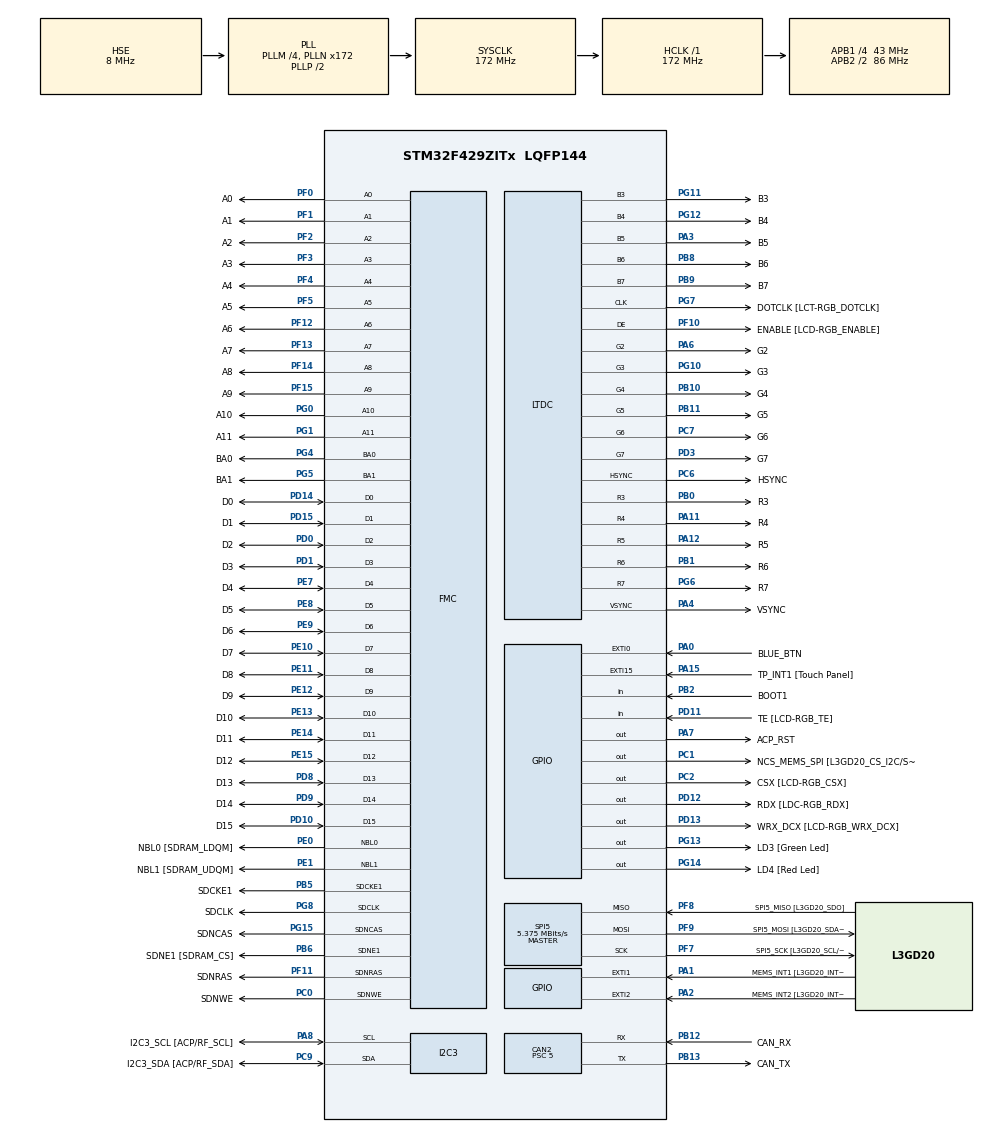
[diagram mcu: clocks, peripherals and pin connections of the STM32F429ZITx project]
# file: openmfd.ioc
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CAN2.BS1=CAN_BS1_15TQ
CAN2.BS2=CAN_BS2_2TQ
CAN2.CalculateBaudRate=477777
CAN2.CalculateTimeBit=2093
CAN2.CalculateTimeQuantum=116.27906976744185
CAN2.Prescaler=5
CAN2.SJW=CAN_SJW_1TQ
FMC.CASLatency1=FMC_SDRAM_CAS_LATENCY_3
FMC.ExitSelfRefreshDelay1=7
FMC.LoadToActiveDelay1=2
FMC.RCDDelay1=2
FMC.RPDelay1=2
FMC.RPDelay2=2
FMC.ReadBurst1=FMC_SDRAM_RBURST_DISABLE
FMC.ReadPipeDelay1=FMC_SDRAM_RPIPE_DELAY_1
FMC.ReadPipeDelay2=FMC_SDRAM_RPIPE_DELAY_1
FMC.RowCycleDelay1=7
FMC.RowCycleDelay2=7
FMC.SDClockPeriod1=FMC_SDRAM_CLOCK_PERIOD_2
FMC.SDClockPeriod2=FMC_SDRAM_CLOCK_PERIOD_2
FMC.SelfRefreshTime1=4
FMC.WriteRecoveryTime1=3
FREERTOS.Queues01=DataQueue,16,uint16_t,0,Dynamic,NULL,NULL
FREERTOS.Tasks01=hardwareTask,24,512,StartHardwareTask,Default,NULL,Dynamic,NULL,NULL;touchGFXTask,24,8192,StartTGFXTask,Default,NULL,Dynamic,NULL,NULL;lcdDebugTask,24,512,StartLcdDebugTask,Default,NULL,Dynamic,NULL,NULL
FREERTOS.configCHECK_FOR_STACK_OVERFLOW=2
FREERTOS.configTOTAL_HEAP_SIZE=64000
FREERTOS.configUSE_APPLICATION_TASK_TAG=1
FREERTOS.configUSE_COUNTING_SEMAPHORES=1
FREERTOS.configUSE_IDLE_HOOK=1
FREERTOS.configUSE_MALLOC_FAILED_HOOK=1
FREERTOS.configUSE_RECURSIVE_MUTEXES=1
LTDC.ActiveH=240
LTDC.ActiveW=320
LTDC.Alpha_L0=255
LTDC.BlendingFactor1_L0=LTDC_BLENDING_FACTOR1_CA
LTDC.BlendingFactor2_L0=LTDC_BLENDING_FACTOR2_CA
LTDC.DEPolarity=LTDC_DEPOLARITY_AL
LTDC.FBStartAdress_L0=0xD0000000
LTDC.HBP=59
LTDC.HFP=16
LTDC.HSPolarity=LTDC_HSPOLARITY_AL
LTDC.HSync=31
LTDC.ImageHeight_L0=234
LTDC.ImageWidth_L0=320
LTDC.Layers=0
LTDC.PCPolarity=LTDC_PCPOLARITY_IPC
LTDC.PixelFormat_L0=LTDC_PIXEL_FORMAT_RGB565
LTDC.VBP=15
LTDC.VFP=4
LTDC.VSPolarity=LTDC_VSPOLARITY_AL
LTDC.VSync=3
LTDC.WindowX0_L0=0
LTDC.WindowX1_L0=320
LTDC.WindowY0_L0=0
LTDC.WindowY1_L0=234
Mcu.Family=STM32F4
Mcu.Name=STM32F429ZITx
Mcu.Package=LQFP144
NVIC.CAN2_RX0_IRQn=true\:5\:0\:false\:false\:true\:true\:true\:true\:true
NVIC.DMA2D_IRQn=true\:5\:0\:true\:false\:true\:true\:true\:true\:true
NVIC.EXTI0_IRQn=true\:5\:0\:false\:false\:true\:true\:true\:true\:true
NVIC.LTDC_IRQn=true\:5\:0\:true\:false\:true\:true\:true\:true\:true
NVIC.PriorityGroup=NVIC_PRIORITYGROUP_4
NVIC.TIM6_DAC_IRQn=true\:0\:0\:false\:false\:true\:false\:false\:true\:true
NVIC.TimeBase=TIM6_DAC_IRQn
NVIC.TimeBaseIP=TIM6
PA0/WKUP.GPIO_Label=BLUE_BTN
PA0/WKUP.GPIO_ModeDefaultEXTI=GPIO_MODE_IT_FALLING
PA0/WKUP.Signal=GPXTI0
PA1.GPIO_Label=MEMS_INT1 [L3GD20_INT1]
PA1.GPIO_ModeDefaultEXTI=GPIO_MODE_EVT_RISING
PA1.GPIO_PuPd=GPIO_NOPULL
PA1.Signal=GPXTI1
PA11.GPIO_Label=R4
PA11.GPIO_Mode=GPIO_MODE_AF_PP
PA11.GPIO_PuPd=GPIO_NOPULL
PA11.GPIO_Speed=GPIO_SPEED_FREQ_VERY_HIGH
PA11.Mode=RGB565
PA11.Signal=LTDC_R4
PA12.GPIO_Label=R5
PA12.GPIO_Mode=GPIO_MODE_AF_PP
PA12.GPIO_PuPd=GPIO_NOPULL
PA12.GPIO_Speed=GPIO_SPEED_FREQ_VERY_HIGH
PA12.Mode=RGB565
PA12.Signal=LTDC_R5
PA13.GPIO_Label=SWDIO
PA13.Mode=Serial_Wire
PA13.Signal=SYS_JTMS-SWDIO
PA14.GPIO_Label=SWCLK
PA14.Mode=Serial_Wire
PA14.Signal=SYS_JTCK-SWCLK
PA15.GPIO_Label=TP_INT1 [Touch Panel]
PA15.GPIO_ModeDefaultEXTI=GPIO_MODE_EVT_RISING
PA15.GPIO_PuPd=GPIO_NOPULL
PA15.Signal=GPXTI15
PA2.GPIO_Label=MEMS_INT2 [L3GD20_INT2]
PA2.GPIO_ModeDefaultEXTI=GPIO_MODE_EVT_RISING
PA2.GPIO_PuPd=GPIO_NOPULL
PA2.Signal=GPXTI2
PA3.GPIO_Label=B5
PA3.GPIO_Mode=GPIO_MODE_AF_PP
PA3.GPIO_PuPd=GPIO_NOPULL
PA3.GPIO_Speed=GPIO_SPEED_FREQ_LOW
PA3.Mode=RGB565
PA3.Signal=LTDC_B5
PA4.GPIO_Label=VSYNC
PA4.GPIO_Mode=GPIO_MODE_AF_PP
PA4.GPIO_PuPd=GPIO_NOPULL
PA4.GPIO_Speed=GPIO_SPEED_FREQ_LOW
PA4.Mode=RGB565
PA4.Signal=LTDC_VSYNC
PA6.GPIO_Label=G2
PA6.GPIO_Mode=GPIO_MODE_AF_PP
PA6.GPIO_PuPd=GPIO_NOPULL
PA6.GPIO_Speed=GPIO_SPEED_FREQ_VERY_HIGH
PA6.Mode=RGB565
PA6.Signal=LTDC_G2
PA7.GPIO_Label=ACP_RST
PA7.GPIO_Mode=GPIO_MODE_OUTPUT_PP
PA7.GPIO_PuPd=GPIO_NOPULL
PA7.GPIO_Speed=GPIO_SPEED_FREQ_LOW
PA7.Signal=GPIO_Output
PA8.GPIO_Label=I2C3_SCL [ACP/RF_SCL]
PA8.GPIO_Mode=GPIO_MODE_AF_OD
PA8.GPIO_Pu=GPIO_PULLUP
PA8.GPIO_PuPd=GPIO_NOPULL
PA8.GPIO_Speed=GPIO_SPEED_FREQ_LOW
PA8.Mode=I2C
PA8.Signal=I2C3_SCL
PB0.GPIO_Label=R3
PB0.GPIO_Mode=GPIO_MODE_AF_PP
PB0.GPIO_PuPd=GPIO_NOPULL
PB0.GPIO_Speed=GPIO_SPEED_FREQ_VERY_HIGH
PB0.Mode=RGB565
PB0.Signal=LTDC_R3
PB1.GPIO_Label=R6
PB1.GPIO_Mode=GPIO_MODE_AF_PP
PB1.GPIO_PuPd=GPIO_NOPULL
PB1.GPIO_Speed=GPIO_SPEED_FREQ_VERY_HIGH
PB1.Mode=RGB565
PB1.Signal=LTDC_R6
PB10.GPIO_Label=G4
PB10.GPIO_Mode=GPIO_MODE_AF_PP
PB10.GPIO_PuPd=GPIO_NOPULL
PB10.GPIO_Speed=GPIO_SPEED_FREQ_VERY_HIGH
PB10.Mode=RGB565
PB10.Signal=LTDC_G4
PB11.GPIO_Label=G5
PB11.GPIO_Mode=GPIO_MODE_AF_PP
PB11.GPIO_PuPd=GPIO_NOPULL
PB11.GPIO_Speed=GPIO_SPEED_FREQ_VERY_HIGH
PB11.Mode=RGB565
PB11.Signal=LTDC_G5
PB12.GPIO_Label=CAN_RX
PB12.GPIO_Speed=GPIO_SPEED_FREQ_VERY_HIGH
PB12.Mode=CAN_Activate
PB12.Signal=CAN2_RX
PB13.GPIO_Label=CAN_TX
PB13.GPIO_Mode=GPIO_MODE_AF_PP
PB13.Mode=CAN_Activate
PB13.Signal=CAN2_TX
PB2/BOOT1.GPIO_Label=BOOT1
PB2/BOOT1.GPIO_Mode=GPIO_MODE_INPUT
PB2/BOOT1.GPIO_PuPd=GPIO_NOPULL
PB2/BOOT1.Signal=GPIO_Input
PB5.GPIO_Label=SDCKE1
PB5.GPIO_Mode=GPIO_MODE_AF_PP
PB5.GPIO_PuPd=GPIO_NOPULL
PB5.GPIO_Speed=GPIO_SPEED_FREQ_VERY_HIGH
PB5.Mode=SdramChipSelect2_1
PB5.Signal=FMC_SDCKE1
PB6.GPIO_Label=SDNE1 [SDRAM_CS]
PB6.GPIO_Mode=GPIO_MODE_AF_PP
PB6.GPIO_PuPd=GPIO_NOPULL
PB6.GPIO_Speed=GPIO_SPEED_FREQ_VERY_HIGH
PB6.Mode=SdramChipSelect2_1
PB6.Signal=FMC_SDNE1
PB8.GPIO_Label=B6
PB8.GPIO_Mode=GPIO_MODE_AF_PP
PB8.GPIO_PuPd=GPIO_NOPULL
PB8.GPIO_Speed=GPIO_SPEED_FREQ_VERY_HIGH
PB8.Mode=RGB565
PB8.Signal=LTDC_B6
PB9.GPIO_Label=B7
PB9.GPIO_Mode=GPIO_MODE_AF_PP
PB9.GPIO_PuPd=GPIO_NOPULL
PB9.GPIO_Speed=GPIO_SPEED_FREQ_VERY_HIGH
PB9.Mode=RGB565
PB9.Signal=LTDC_B7
PC0.GPIO_Label=SDNWE
PC0.GPIO_Mode=GPIO_MODE_AF_PP
PC0.GPIO_PuPd=GPIO_NOPULL
PC0.GPIO_Speed=GPIO_SPEED_FREQ_VERY_HIGH
PC0.Signal=FMC_SDNWE
PC1.GPIO_Label=NCS_MEMS_SPI [L3GD20_CS_I2C/SPI]
PC1.GPIO_Mode=GPIO_MODE_OUTPUT_PP
PC1.GPIO_PuPd=GPIO_NOPULL
PC1.GPIO_Speed=GPIO_SPEED_FREQ_LOW
PC1.Signal=GPIO_Output
PC10.GPIO_Label=R2
PC10.GPIO_Mode=GPIO_MODE_AF_PP
PC10.GPIO_PuPd=GPIO_NOPULL
PC10.GPIO_Speed=GPIO_SPEED_FREQ_LOW
PC10.Signal=LTDC_R2
PC2.GPIO_Label=CSX [LCD-RGB_CSX]
PC2.GPIO_Mode=GPIO_MODE_OUTPUT_PP
PC2.GPIO_PuPd=GPIO_NOPULL
PC2.GPIO_Speed=GPIO_SPEED_FREQ_LOW
PC2.Signal=GPIO_Output
PC6.GPIO_Label=HSYNC
PC6.GPIO_Mode=GPIO_MODE_AF_PP
PC6.GPIO_PuPd=GPIO_NOPULL
PC6.GPIO_Speed=GPIO_SPEED_FREQ_VERY_HIGH
PC6.Mode=RGB565
PC6.Signal=LTDC_HSYNC
PC7.GPIO_Label=G6
PC7.GPIO_Mode=GPIO_MODE_AF_PP
PC7.GPIO_PuPd=GPIO_NOPULL
PC7.GPIO_Speed=GPIO_SPEED_FREQ_VERY_HIGH
PC7.Mode=RGB565
PC7.Signal=LTDC_G6
PC9.GPIO_Label=I2C3_SDA [ACP/RF_SDA]
PC9.GPIO_Mode=GPIO_MODE_AF_OD
PC9.GPIO_Pu=GPIO_PULLUP
PC9.GPIO_PuPd=GPIO_NOPULL
PC9.GPIO_Speed=GPIO_SPEED_FREQ_LOW
PC9.Mode=I2C
PC9.Signal=I2C3_SDA
PD0.GPIO_Label=D2
PD0.GPIO_Mode=GPIO_MODE_AF_PP
PD0.GPIO_PuPd=GPIO_NOPULL
PD0.GPIO_Speed=GPIO_SPEED_FREQ_VERY_HIGH
PD0.Signal=FMC_D2_DA2
PD1.GPIO_Label=D3
PD1.GPIO_Mode=GPIO_MODE_AF_PP
PD1.GPIO_PuPd=GPIO_NOPULL
PD1.GPIO_Speed=GPIO_SPEED_FREQ_VERY_HIGH
PD1.Signal=FMC_D3_DA3
PD10.GPIO_Label=D15
PD10.GPIO_Mode=GPIO_MODE_AF_PP
PD10.GPIO_PuPd=GPIO_NOPULL
PD10.GPIO_Speed=GPIO_SPEED_FREQ_VERY_HIGH
PD10.Signal=FMC_D15_DA15
PD11.GPIO_Label=TE [LCD-RGB_TE]
PD11.GPIO_Mode=GPIO_MODE_INPUT
PD11.GPIO_PuPd=GPIO_NOPULL
PD11.Signal=GPIO_Input
PD12.GPIO_Label=RDX [LDC-RGB_RDX]
PD12.GPIO_Mode=GPIO_MODE_OUTPUT_PP
PD12.GPIO_PuPd=GPIO_NOPULL
PD12.GPIO_Speed=GPIO_SPEED_FREQ_LOW
PD12.Signal=GPIO_Output
PD13.GPIO_Label=WRX_DCX [LCD-RGB_WRX_DCX]
PD13.GPIO_Mode=GPIO_MODE_OUTPUT_PP
PD13.GPIO_PuPd=GPIO_NOPULL
PD13.GPIO_Speed=GPIO_SPEED_FREQ_LOW
PD13.Signal=GPIO_Output
PD14.GPIO_Label=D0
PD14.GPIO_Mode=GPIO_MODE_AF_PP
PD14.GPIO_PuPd=GPIO_NOPULL
PD14.GPIO_Speed=GPIO_SPEED_FREQ_VERY_HIGH
PD14.Signal=FMC_D0_DA0
PD15.GPIO_Label=D1
PD15.GPIO_Mode=GPIO_MODE_AF_PP
PD15.GPIO_PuPd=GPIO_NOPULL
PD15.GPIO_Speed=GPIO_SPEED_FREQ_VERY_HIGH
PD15.Signal=FMC_D1_DA1
PD3.GPIO_Label=G7
PD3.GPIO_Mode=GPIO_MODE_AF_PP
PD3.GPIO_PuPd=GPIO_NOPULL
PD3.GPIO_Speed=GPIO_SPEED_FREQ_VERY_HIGH
PD3.Mode=RGB565
PD3.Signal=LTDC_G7
PD6.GPIO_Label=B2
PD6.GPIO_Mode=GPIO_MODE_AF_PP
PD6.GPIO_PuPd=GPIO_NOPULL
PD6.GPIO_Speed=GPIO_SPEED_FREQ_LOW
PD6.Signal=LTDC_B2
PD8.GPIO_Label=D13
PD8.GPIO_Mode=GPIO_MODE_AF_PP
PD8.GPIO_PuPd=GPIO_NOPULL
PD8.GPIO_Speed=GPIO_SPEED_FREQ_VERY_HIGH
PD8.Signal=FMC_D13_DA13
PD9.GPIO_Label=D14
PD9.GPIO_Mode=GPIO_MODE_AF_PP
PD9.GPIO_PuPd=GPIO_NOPULL
PD9.GPIO_Speed=GPIO_SPEED_FREQ_VERY_HIGH
PD9.Signal=FMC_D14_DA14
PE0.GPIO_Label=NBL0 [SDRAM_LDQM]
PE0.GPIO_Mode=GPIO_MODE_AF_PP
PE0.GPIO_PuPd=GPIO_NOPULL
PE0.GPIO_Speed=GPIO_SPEED_FREQ_VERY_HIGH
PE0.Signal=FMC_NBL0
PE1.GPIO_Label=NBL1 [SDRAM_UDQM]
PE1.GPIO_Mode=GPIO_MODE_AF_PP
PE1.GPIO_PuPd=GPIO_NOPULL
PE1.GPIO_Speed=GPIO_SPEED_FREQ_VERY_HIGH
PE1.Signal=FMC_NBL1
PE10.GPIO_Label=D7
PE10.GPIO_Mode=GPIO_MODE_AF_PP
PE10.GPIO_PuPd=GPIO_NOPULL
PE10.GPIO_Speed=GPIO_SPEED_FREQ_VERY_HIGH
PE10.Signal=FMC_D7_DA7
PE11.GPIO_Label=D8
PE11.GPIO_Mode=GPIO_MODE_AF_PP
PE11.GPIO_PuPd=GPIO_NOPULL
PE11.GPIO_Speed=GPIO_SPEED_FREQ_VERY_HIGH
PE11.Signal=FMC_D8_DA8
PE12.GPIO_Label=D9
PE12.GPIO_Mode=GPIO_MODE_AF_PP
PE12.GPIO_PuPd=GPIO_NOPULL
PE12.GPIO_Speed=GPIO_SPEED_FREQ_VERY_HIGH
PE12.Signal=FMC_D9_DA9
PE13.GPIO_Label=D10
PE13.GPIO_Mode=GPIO_MODE_AF_PP
PE13.GPIO_PuPd=GPIO_NOPULL
PE13.GPIO_Speed=GPIO_SPEED_FREQ_VERY_HIGH
PE13.Signal=FMC_D10_DA10
PE14.GPIO_Label=D11
PE14.GPIO_Mode=GPIO_MODE_AF_PP
PE14.GPIO_PuPd=GPIO_NOPULL
PE14.GPIO_Speed=GPIO_SPEED_FREQ_VERY_HIGH
PE14.Signal=FMC_D11_DA11
PE15.GPIO_Label=D12
PE15.GPIO_Mode=GPIO_MODE_AF_PP
PE15.GPIO_PuPd=GPIO_NOPULL
PE15.GPIO_Speed=GPIO_SPEED_FREQ_VERY_HIGH
PE15.Signal=FMC_D12_DA12
PE7.GPIO_Label=D4
PE7.GPIO_Mode=GPIO_MODE_AF_PP
PE7.GPIO_PuPd=GPIO_NOPULL
PE7.GPIO_Speed=GPIO_SPEED_FREQ_VERY_HIGH
PE7.Signal=FMC_D4_DA4
PE8.GPIO_Label=D5
PE8.GPIO_Mode=GPIO_MODE_AF_PP
PE8.GPIO_PuPd=GPIO_NOPULL
PE8.GPIO_Speed=GPIO_SPEED_FREQ_VERY_HIGH
PE8.Signal=FMC_D5_DA5
PE9.GPIO_Label=D6
PE9.GPIO_Mode=GPIO_MODE_AF_PP
PE9.GPIO_PuPd=GPIO_NOPULL
PE9.GPIO_Speed=GPIO_SPEED_FREQ_VERY_HIGH
PE9.Signal=FMC_D6_DA6
PF0.GPIO_Label=A0
PF0.GPIO_Mode=GPIO_MODE_AF_PP
PF0.GPIO_PuPd=GPIO_NOPULL
PF0.GPIO_Speed=GPIO_SPEED_FREQ_VERY_HIGH
PF0.Signal=FMC_A0
PF1.GPIO_Label=A1
PF1.GPIO_Mode=GPIO_MODE_AF_PP
PF1.GPIO_PuPd=GPIO_NOPULL
PF1.GPIO_Speed=GPIO_SPEED_FREQ_VERY_HIGH
PF1.Signal=FMC_A1
PF10.GPIO_Label=ENABLE [LCD-RGB_ENABLE]
PF10.GPIO_Mode=GPIO_MODE_AF_PP
PF10.GPIO_PuPd=GPIO_NOPULL
PF10.GPIO_Speed=GPIO_SPEED_FREQ_VERY_HIGH
PF10.Mode=RGB565
PF10.Signal=LTDC_DE
PF11.GPIO_Label=SDNRAS
PF11.GPIO_Mode=GPIO_MODE_AF_PP
PF11.GPIO_PuPd=GPIO_NOPULL
PF11.GPIO_Speed=GPIO_SPEED_FREQ_VERY_HIGH
PF11.Signal=FMC_SDNRAS
PF12.GPIO_Label=A6
PF12.GPIO_Mode=GPIO_MODE_AF_PP
PF12.GPIO_PuPd=GPIO_NOPULL
PF12.GPIO_Speed=GPIO_SPEED_FREQ_VERY_HIGH
PF12.Signal=FMC_A6
PF13.GPIO_Label=A7
PF13.GPIO_Mode=GPIO_MODE_AF_PP
PF13.GPIO_PuPd=GPIO_NOPULL
PF13.GPIO_Speed=GPIO_SPEED_FREQ_VERY_HIGH
PF13.Signal=FMC_A7
PF14.GPIO_Label=A8
PF14.GPIO_Mode=GPIO_MODE_AF_PP
PF14.GPIO_PuPd=GPIO_NOPULL
PF14.GPIO_Speed=GPIO_SPEED_FREQ_VERY_HIGH
PF14.Signal=FMC_A8
PF15.GPIO_Label=A9
PF15.GPIO_Mode=GPIO_MODE_AF_PP
PF15.GPIO_PuPd=GPIO_NOPULL
PF15.GPIO_Speed=GPIO_SPEED_FREQ_VERY_HIGH
PF15.Signal=FMC_A9
PF2.GPIO_Label=A2
PF2.GPIO_Mode=GPIO_MODE_AF_PP
PF2.GPIO_PuPd=GPIO_NOPULL
PF2.GPIO_Speed=GPIO_SPEED_FREQ_VERY_HIGH
PF2.Signal=FMC_A2
PF3.GPIO_Label=A3
PF3.GPIO_Mode=GPIO_MODE_AF_PP
PF3.GPIO_PuPd=GPIO_NOPULL
PF3.GPIO_Speed=GPIO_SPEED_FREQ_VERY_HIGH
PF3.Signal=FMC_A3
PF4.GPIO_Label=A4
PF4.GPIO_Mode=GPIO_MODE_AF_PP
PF4.GPIO_PuPd=GPIO_NOPULL
PF4.GPIO_Speed=GPIO_SPEED_FREQ_VERY_HIGH
PF4.Signal=FMC_A4
PF5.GPIO_Label=A5
PF5.GPIO_Mode=GPIO_MODE_AF_PP
PF5.GPIO_PuPd=GPIO_NOPULL
PF5.GPIO_Speed=GPIO_SPEED_FREQ_VERY_HIGH
PF5.Signal=FMC_A5
PF7.GPIO_Label=SPI5_SCK [L3GD20_SCL/SPC]
PF7.GPIO_Mode=GPIO_MODE_AF_PP
PF7.GPIO_PuPd=GPIO_NOPULL
PF7.GPIO_Speed=GPIO_SPEED_FREQ_LOW
PF7.Mode=Full_Duplex_Master
PF7.Signal=SPI5_SCK
PF8.GPIO_Label=SPI5_MISO [L3GD20_SDO]
PF8.GPIO_Mode=GPIO_MODE_AF_PP
PF8.GPIO_PuPd=GPIO_NOPULL
PF8.GPIO_Speed=GPIO_SPEED_FREQ_LOW
PF8.Mode=Full_Duplex_Master
PF8.Signal=SPI5_MISO
PF9.GPIO_Label=SPI5_MOSI [L3GD20_SDA/SDI/SDO]
PF9.GPIO_Mode=GPIO_MODE_AF_PP
PF9.GPIO_PuPd=GPIO_NOPULL
PF9.GPIO_Speed=GPIO_SPEED_FREQ_LOW
PF9.Mode=Full_Duplex_Master
PF9.Signal=SPI5_MOSI
PG0.GPIO_Label=A10
PG0.GPIO_Mode=GPIO_MODE_AF_PP
PG0.GPIO_PuPd=GPIO_NOPULL
PG0.GPIO_Speed=GPIO_SPEED_FREQ_VERY_HIGH
PG0.Signal=FMC_A10
PG1.GPIO_Label=A11
PG1.GPIO_Mode=GPIO_MODE_AF_PP
PG1.GPIO_PuPd=GPIO_NOPULL
PG1.GPIO_Speed=GPIO_SPEED_FREQ_VERY_HIGH
PG1.Signal=FMC_A11
PG10.GPIO_Label=G3
PG10.GPIO_Mode=GPIO_MODE_AF_PP
PG10.GPIO_PuPd=GPIO_NOPULL
PG10.GPIO_Speed=GPIO_SPEED_FREQ_VERY_HIGH
PG10.Mode=RGB565
PG10.Signal=LTDC_G3
PG11.GPIO_Label=B3
PG11.GPIO_Mode=GPIO_MODE_AF_PP
PG11.GPIO_PuPd=GPIO_NOPULL
PG11.GPIO_Speed=GPIO_SPEED_FREQ_VERY_HIGH
PG11.Mode=RGB565
PG11.Signal=LTDC_B3
PG12.GPIO_Label=B4
PG12.GPIO_Mode=GPIO_MODE_AF_PP
PG12.GPIO_PuPd=GPIO_NOPULL
PG12.GPIO_Speed=GPIO_SPEED_FREQ_VERY_HIGH
PG12.Mode=RGB565
PG12.Signal=LTDC_B4
PG13.GPIO_Label=LD3 [Green Led]
PG13.GPIO_Mode=GPIO_MODE_OUTPUT_PP
PG13.GPIO_PuPd=GPIO_NOPULL
PG13.GPIO_Speed=GPIO_SPEED_FREQ_LOW
PG13.Signal=GPIO_Output
PG14.GPIO_Label=LD4 [Red Led]
PG14.GPIO_Mode=GPIO_MODE_OUTPUT_PP
PG14.GPIO_PuPd=GPIO_NOPULL
PG14.GPIO_Speed=GPIO_SPEED_FREQ_LOW
PG14.Signal=GPIO_Output
PG15.GPIO_Label=SDNCAS
PG15.GPIO_Mode=GPIO_MODE_AF_PP
PG15.GPIO_PuPd=GPIO_NOPULL
PG15.GPIO_Speed=GPIO_SPEED_FREQ_VERY_HIGH
PG15.Signal=FMC_SDNCAS
PG4.GPIO_Label=BA0
PG4.GPIO_Mode=GPIO_MODE_AF_PP
PG4.GPIO_PuPd=GPIO_NOPULL
PG4.GPIO_Speed=GPIO_SPEED_FREQ_VERY_HIGH
PG4.Signal=FMC_A14_BA0
PG5.GPIO_Label=BA1
PG5.GPIO_Mode=GPIO_MODE_AF_PP
PG5.GPIO_PuPd=GPIO_NOPULL
PG5.GPIO_Speed=GPIO_SPEED_FREQ_VERY_HIGH
PG5.Signal=FMC_A15_BA1
PG6.GPIO_Label=R7
PG6.GPIO_Mode=GPIO_MODE_AF_PP
PG6.GPIO_PuPd=GPIO_NOPULL
PG6.GPIO_Speed=GPIO_SPEED_FREQ_VERY_HIGH
PG6.Mode=RGB565
PG6.Signal=LTDC_R7
PG7.GPIO_Label=DOTCLK [LCT-RGB_DOTCLK]
PG7.GPIO_Mode=GPIO_MODE_AF_PP
PG7.GPIO_PuPd=GPIO_NOPULL
PG7.GPIO_Speed=GPIO_SPEED_FREQ_VERY_HIGH
PG7.Mode=RGB565
PG7.Signal=LTDC_CLK
PG8.GPIO_Label=SDCLK
PG8.GPIO_Mode=GPIO_MODE_AF_PP
PG8.GPIO_PuPd=GPIO_NOPULL
PG8.GPIO_Speed=GPIO_SPEED_FREQ_VERY_HIGH
PG8.Signal=FMC_SDCLK
PH0/OSC_IN.GPIO_Label=PH0-OSC_IN
PH0/OSC_IN.Mode=HSE-External-Oscillator
PH0/OSC_IN.Signal=RCC_OSC_IN
PH1/OSC_OUT.GPIO_Label=PH1-OSC_OUT
PH1/OSC_OUT.Mode=HSE-External-Oscillator
PH1/OSC_OUT.Signal=RCC_OSC_OUT
ProjectManager.HeapSize=0x200
ProjectManager.StackSize=0x400
ProjectManager.TargetToolchain=STM32CubeIDE
RCC.48MHZClocksFreq_Value=43000000
RCC.AHBFreq_Value=172000000
RCC.APB1CLKDivider=RCC_HCLK_DIV4
RCC.APB1Freq_Value=43000000
RCC.APB1TimFreq_Value=86000000
RCC.APB2CLKDivider=RCC_HCLK_DIV2
RCC.APB2Freq_Value=86000000
RCC.APB2TimFreq_Value=172000000
RCC.CortexFreq_Value=172000000
RCC.HCLKFreq_Value=172000000
RCC.HSE_VALUE=8000000
RCC.HSI_VALUE=16000000
RCC.LSE_VALUE=32768
RCC.PLLM=4
RCC.PLLN=172
RCC.PLLQ=8
RCC.PLLSAIN=54
RCC.PLLSourceVirtual=RCC_PLLSOURCE_HSE
RCC.SYSCLKFreq_VALUE=172000000
RCC.SYSCLKSource=RCC_SYSCLKSOURCE_PLLCLK
RCC.VCOOutputFreq_Value=344000000
SH.FMC_A0.0=FMC_A0,12b-sda1
SH.FMC_A1.0=FMC_A1,12b-sda1
SH.FMC_A10.0=FMC_A10,12b-sda1
SH.FMC_A11.0=FMC_A11,12b-sda1
SH.FMC_A14_BA0.0=FMC_BA0,FourSdramBanks1
SH.FMC_A15_BA1.0=FMC_BA1,FourSdramBanks1
SH.FMC_A2.0=FMC_A2,12b-sda1
SH.FMC_A3.0=FMC_A3,12b-sda1
SH.FMC_A4.0=FMC_A4,12b-sda1
SH.FMC_A5.0=FMC_A5,12b-sda1
SH.FMC_A6.0=FMC_A6,12b-sda1
SH.FMC_A7.0=FMC_A7,12b-sda1
SH.FMC_A8.0=FMC_A8,12b-sda1
SH.FMC_A9.0=FMC_A9,12b-sda1
SH.FMC_D0_DA0.0=FMC_D0,sd-16b-d1
SH.FMC_D10_DA10.0=FMC_D10,sd-16b-d1
SH.FMC_D11_DA11.0=FMC_D11,sd-16b-d1
SH.FMC_D12_DA12.0=FMC_D12,sd-16b-d1
SH.FMC_D13_DA13.0=FMC_D13,sd-16b-d1
SH.FMC_D14_DA14.0=FMC_D14,sd-16b-d1
SH.FMC_D15_DA15.0=FMC_D15,sd-16b-d1
SH.FMC_D1_DA1.0=FMC_D1,sd-16b-d1
SH.FMC_D2_DA2.0=FMC_D2,sd-16b-d1
SH.FMC_D3_DA3.0=FMC_D3,sd-16b-d1
SH.FMC_D4_DA4.0=FMC_D4,sd-16b-d1
SH.FMC_D5_DA5.0=FMC_D5,sd-16b-d1
SH.FMC_D6_DA6.0=FMC_D6,sd-16b-d1
SH.FMC_D7_DA7.0=FMC_D7,sd-16b-d1
SH.FMC_D8_DA8.0=FMC_D8,sd-16b-d1
SH.FMC_D9_DA9.0=FMC_D9,sd-16b-d1
SH.FMC_NBL0.0=FMC_NBL0,Sd2ByteEnable1
SH.FMC_NBL1.0=FMC_NBL1,Sd2ByteEnable1
SH.FMC_SDCLK.0=FMC_SDCLK,12b-sda1
SH.FMC_SDNCAS.0=FMC_SDNCAS,12b-sda1
SH.FMC_SDNRAS.0=FMC_SDNRAS,12b-sda1
SH.FMC_SDNWE.0=FMC_SDNWE,12b-sda1
SPI5.BaudRatePrescaler=SPI_BAUDRATEPRESCALER_16
SPI5.CalculateBaudRate=5.375 MBits/s
SPI5.Direction=SPI_DIRECTION_2LINES
SPI5.Mode=SPI_MODE_MASTER
SPI5.VirtualType=VM_MASTER
STMicroelectronics.X-CUBE-TOUCHGFX.4.20.0.ApplicationCcGraphicsJjApplication=TouchGFXOoGenerator
STMicroelectronics.X-CUBE-TOUCHGFX.4.20.0.tgfx_address1=0xD0000000
STMicroelectronics.X-CUBE-TOUCHGFX.4.20.0.tgfx_address2=0xD0025800
STMicroelectronics.X-CUBE-TOUCHGFX.4.20.0.tgfx_buffering_strategy=Double
STMicroelectronics.X-CUBE-TOUCHGFX.4.20.0.tgfx_display_interface=disp_ltdc
STMicroelectronics.X-CUBE-TOUCHGFX.4.20.0.tgfx_hardware_accelerator=dma_2d
STMicroelectronics.X-CUBE-TOUCHGFX.4.20.0.tgfx_location=By Address
STMicroelectronics.X-CUBE-TOUCHGFX.4.20.0.tgfx_vsync=vsync_ltdc
STMicroelectronics.X-CUBE-TOUCHGFX.4.20.0_IsPackSelfContextualization=true
VP_CRC_VS_CRC.Mode=CRC_Activate
VP_DMA2D_VS_DMA2D.Mode=DMA2D_Activate
VP_FREERTOS_VS_CMSIS_V2.Mode=CMSIS_V2
VP_RNG_VS_RNG.Mode=RNG_Activate
VP_STMicroelectronics.X-CUBE-TOUCHGFX_VS_GraphicsJjApplication_4.20.0.Mode=GraphicsJjApplication
VP_SYS_VS_tim6.Mode=TIM6
VP_TIM1_VS_ClockSourceINT.Mode=Internal
board=STM32F429I-DISC1

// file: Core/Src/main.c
/* USER CODE BEGIN Header */
/**
  ******************************************************************************
  * @file           : main.c
  * @brief          : Main program body
  ******************************************************************************
  * @attention
  *
  * Copyright (c) 2022 STMicroelectronics.
  * All rights reserved.
  *
  * This software is licensed under terms that can be found in the LICENSE file
  * in the root directory of this software component.
  * If no LICENSE file comes with this software, it is provided AS-IS.
  *
  ******************************************************************************
  */
/* USER CODE END Header */
#include "main.h"
#include "cmsis_os.h"
#include "app_touchgfx.h"

/* USER CODE BEGIN Includes */
#include "stdbool.h"
#include "comm.h"
#include "ili9341/ili9341.h"
#include "data.h"
#include "debug_screen.h"
#include "debug_data.h"
/* USER CODE END Includes */

/* USER CODE BEGIN PD */
#define REFRESH_COUNT           ((uint32_t)1386)   /* SDRAM refresh counter */
#define SDRAM_TIMEOUT           ((uint32_t)0xFFFF)

/**
  * @brief  FMC SDRAM Mode definition register defines
  */
#define SDRAM_MODEREG_BURST_LENGTH_1             ((uint16_t)0x0000)
#define SDRAM_MODEREG_BURST_LENGTH_2             ((uint16_t)0x0001)
#define SDRAM_MODEREG_BURST_LENGTH_4             ((uint16_t)0x0002)
#define SDRAM_MODEREG_BURST_LENGTH_8             ((uint16_t)0x0004)
#define SDRAM_MODEREG_BURST_TYPE_SEQUENTIAL      ((uint16_t)0x0000)
#define SDRAM_MODEREG_BURST_TYPE_INTERLEAVED     ((uint16_t)0x0008)
#define SDRAM_MODEREG_CAS_LATENCY_2              ((uint16_t)0x0020)
#define SDRAM_MODEREG_CAS_LATENCY_3              ((uint16_t)0x0030)
#define SDRAM_MODEREG_OPERATING_MODE_STANDARD    ((uint16_t)0x0000)
#define SDRAM_MODEREG_WRITEBURST_MODE_PROGRAMMED ((uint16_t)0x0000)
#define SDRAM_MODEREG_WRITEBURST_MODE_SINGLE     ((uint16_t)0x0200)

#define I2C3_TIMEOUT_MAX                    0x3000 /*<! The value of the maximal timeout for I2C waiting loops */
#define SPI5_TIMEOUT_MAX                    0x1000
/* USER CODE END PD */

CAN_HandleTypeDef hcan2;

CRC_HandleTypeDef hcrc;

DMA2D_HandleTypeDef hdma2d;

I2C_HandleTypeDef hi2c3;

LTDC_HandleTypeDef hltdc;

RNG_HandleTypeDef hrng;

SPI_HandleTypeDef hspi5;

TIM_HandleTypeDef htim1;

SDRAM_HandleTypeDef hsdram1;

/* Definitions for hardwareTask */
osThreadId_t hardwareTaskHandle;
const osThreadAttr_t hardwareTask_attributes = {
  .name = "hardwareTask",
  .stack_size = 512 * 4,
  .priority = (osPriority_t) osPriorityNormal,
};
/* Definitions for touchGFXTask */
osThreadId_t touchGFXTaskHandle;
const osThreadAttr_t touchGFXTask_attributes = {
  .name = "touchGFXTask",
  .stack_size = 8192 * 4,
  .priority = (osPriority_t) osPriorityNormal,
};
/* Definitions for lcdDebugTask */
osThreadId_t lcdDebugTaskHandle;
const osThreadAttr_t lcdDebugTask_attributes = {
  .name = "lcdDebugTask",
  .stack_size = 512 * 4,
  .priority = (osPriority_t) osPriorityNormal,
};
/* Definitions for DataQueue */
osMessageQueueId_t DataQueueHandle;
const osMessageQueueAttr_t DataQueue_attributes = {
  .name = "DataQueue"
};

void SystemClock_Config(void);
static void MX_GPIO_Init(void);
static void MX_CRC_Init(void);
static void MX_DMA2D_Init(void);
static void MX_FMC_Init(void);
static void MX_I2C3_Init(void);
static void MX_LTDC_Init(void);
static void MX_SPI5_Init(void);
static void MX_TIM1_Init(void);
static void MX_CAN2_Init(void);
static void MX_RNG_Init(void);
void StartHardwareTask(void *argument);
void StartTGFXTask(void *argument);
void StartLcdDebugTask(void *argument);

/* USER CODE BEGIN PFP */
static void BSP_SDRAM_Initialization_Sequence(SDRAM_HandleTypeDef *hsdram, FMC_SDRAM_CommandTypeDef *Command);

static uint8_t I2C3_ReadData(uint8_t Addr, uint8_t Reg);
static void I2C3_WriteData(uint8_t Addr, uint8_t Reg, uint8_t Value);
static uint8_t I2C3_ReadBuffer(uint8_t Addr, uint8_t Reg, uint8_t *pBuffer, uint16_t Length);

/* IOExpander IO functions */
void IOE_Init(void);
void IOE_ITConfig(void);
void IOE_Delay(uint32_t Delay);
void IOE_Write(uint8_t Addr, uint8_t Reg, uint8_t Value);
uint8_t IOE_Read(uint8_t Addr, uint8_t Reg);
uint16_t IOE_ReadMultiple(uint8_t Addr, uint8_t Reg, uint8_t *pBuffer, uint16_t Length);
/* USER CODE END PFP */

/* USER CODE BEGIN 0 */
uint32_t I2c3Timeout = I2C3_TIMEOUT_MAX; /*<! Value of Timeout when I2C communication fails */

/* USER CODE END 0 */

int main(void)
{

  /* MCU Configuration--------------------------------------------------------*/

  /* Reset of all peripherals, Initializes the Flash interface and the Systick. */
  HAL_Init();

  /* Configure the system clock */
  SystemClock_Config();

  /* Initialize all configured peripherals */
  MX_GPIO_Init();
  MX_CRC_Init();
  MX_DMA2D_Init();
  MX_FMC_Init();
  MX_I2C3_Init();
  MX_LTDC_Init();
  MX_SPI5_Init();
  MX_TIM1_Init();
  MX_CAN2_Init();
  MX_RNG_Init();
  MX_TouchGFX_Init();
  /* Call PreOsInit function */
  MX_TouchGFX_PreOSInit();
  /* USER CODE BEGIN 2 */
  MFD_DataInit();

  // DEBUG Controllers Init
  DBGS_init();
  DBGD_init();

  COMM_init();

  // SW RST
  I2C3_WriteData(0x54, 0x17, 0b00000010);

  // SD Mode Register 1
  I2C3_WriteData(0x54, 0x80, 0x10); // 0b00010000
  // SD standard - NTSC
  // SD luma filter - Luma SSAF
  // SD chroma filter - 1.3 MHz

  // SD Mode Register 2 (0x0B 0b00001011)
  I2C3_WriteData(0x54, 0x82, 0b01001011);
  // SD PrPb SSAF filter - Enabled
  // SD DAC Output 1 - 1
  // SD pedestal - Enabled
  // SD square pixel mode - Disabled
  // SD VCR FF/RW sync - Disabled
  // SD pixel data valid - Disabled
  // SD active video edge control - Disabled

  // SD Mode Register 3
  I2C3_WriteData(0x54, 0x83, 0x04); // 0b00000100
  // SD pedestal YPrPb output - No pedestal on YPrPb
  // SD Output Levels Y - Y = 700 mV/300 mV
  // SD Output Levels PrPb - 700 mV p-p
  // SD vertical blanking interval (VBI) open - Disabled
  // SD closed captioning field control - Closed captioning disabled

  // SD Mode Register 4
  I2C3_WriteData(0x54, 0x84, 0x00); // 0b00000000
  // SD SFL/SCR/TR mode select - Disabled
  // SD active video length - 720 pixels
  // SD chroma - Chroma enabled
  // SD burst - Enabled
  // SD color bars - Disabled
  // SD luma/chroma swap - DAC 2 = luma, DAC 3 = chroma

  // SD Mode Register 5 (0x02 0b00000010)
  I2C3_WriteData(0x54, 0x86, 0b00000010);
  // NTSC color subcarrier adjust - 5.59 μs (must be set for Macrovision compliance)
  // SD EIA/CEA-861B synchronization compliance - Disabled
  // SD horizontal/vertical counter mode (1) - Update field/line counter
  // SD RGB color swap - Normal

  /* (1) When set to 0, the horizontal/vertical counters automatically wrap around at the end of the line/field/frame of the selected standard. When set to 1, the
horizontal/vertical counters are free running and wrap around when external sync signals indicate to do so. */

  // SD Mode Register 6
  I2C3_WriteData(0x54, 0x87, 0x80); // 0b10100000 0xA0 (autodetect) // 0b10000000 0x80 (def)
  // SD Mode Register 7
  I2C3_WriteData(0x54, 0x88, 0x12); // 0b00010010 0x12 (non-interlaced) // 0b00010000 0x10 (interlaced)
  // SD Mode Register 8
  I2C3_WriteData(0x54, 0x8A, 0b00001100); // Mode 2 — Slave Option (Subaddress 0x8A = X X X X X 1 0 0)

  // Color bars
//    I2C3_WriteData(0x54, 0x00, 0b00010010);
//    I2C3_WriteData(0x54, 0x82, 0b11001011); // 0b00001011 (reset) // 0b11001011 (bars)
//    I2C3_WriteData(0x54, 0x84, 0b01000000); // 0b00000000 (reset) // 0b01000000 (bars)

  //  I2C3_WriteData(0x54, 0x87, 0x80);
  //  I2C3_WriteData(0x54, 0x88, 0x12);
  //  volatile uint8_t b1r = I2C3_ReadData(0x55, 0x87);
  //  volatile uint8_t b2r = I2C3_ReadData(0x55, 0x88);

  /* USER CODE END 2 */

  /* Init scheduler */
  osKernelInitialize();

  /* Create the queue(s) */
  /* creation of DataQueue */
  DataQueueHandle = osMessageQueueNew (16, sizeof(uint16_t), &DataQueue_attributes);

  /* Create the thread(s) */
  /* creation of hardwareTask */
  hardwareTaskHandle = osThreadNew(StartHardwareTask, NULL, &hardwareTask_attributes);

  /* creation of touchGFXTask */
  touchGFXTaskHandle = osThreadNew(StartTGFXTask, NULL, &touchGFXTask_attributes);

  /* creation of lcdDebugTask */
  lcdDebugTaskHandle = osThreadNew(StartLcdDebugTask, NULL, &lcdDebugTask_attributes);

  /* Start scheduler */
  osKernelStart();

  /* We should never get here as control is now taken by the scheduler */

  /* Infinite loop */
  while (1)
  {

  }
}

void SystemClock_Config(void)
{
  RCC_OscInitTypeDef RCC_OscInitStruct = {0};
  RCC_ClkInitTypeDef RCC_ClkInitStruct = {0};

  /** Configure the main internal regulator output voltage
  */
  __HAL_RCC_PWR_CLK_ENABLE();
  __HAL_PWR_VOLTAGESCALING_CONFIG(PWR_REGULATOR_VOLTAGE_SCALE1);

  /** Initializes the RCC Oscillators according to the specified parameters
  * in the RCC_OscInitTypeDef structure.
  */
  RCC_OscInitStruct.OscillatorType = RCC_OSCILLATORTYPE_HSE;
  RCC_OscInitStruct.HSEState = RCC_HSE_ON;
  RCC_OscInitStruct.PLL.PLLState = RCC_PLL_ON;
  RCC_OscInitStruct.PLL.PLLSource = RCC_PLLSOURCE_HSE;
  RCC_OscInitStruct.PLL.PLLM = 4;
  RCC_OscInitStruct.PLL.PLLN = 172;
  RCC_OscInitStruct.PLL.PLLP = RCC_PLLP_DIV2;
  RCC_OscInitStruct.PLL.PLLQ = 8;
  if (HAL_RCC_OscConfig(&RCC_OscInitStruct) != HAL_OK)
  {
    Error_Handler();
  }

  /** Activate the Over-Drive mode
  */
  if (HAL_PWREx_EnableOverDrive() != HAL_OK)
  {
    Error_Handler();
  }

  /** Initializes the CPU, AHB and APB buses clocks
  */
  RCC_ClkInitStruct.ClockType = RCC_CLOCKTYPE_HCLK|RCC_CLOCKTYPE_SYSCLK
                              |RCC_CLOCKTYPE_PCLK1|RCC_CLOCKTYPE_PCLK2;
  RCC_ClkInitStruct.SYSCLKSource = RCC_SYSCLKSOURCE_PLLCLK;
  RCC_ClkInitStruct.AHBCLKDivider = RCC_SYSCLK_DIV1;
  RCC_ClkInitStruct.APB1CLKDivider = RCC_HCLK_DIV4;
  RCC_ClkInitStruct.APB2CLKDivider = RCC_HCLK_DIV2;

  if (HAL_RCC_ClockConfig(&RCC_ClkInitStruct, FLASH_LATENCY_5) != HAL_OK)
  {
    Error_Handler();
  }
}

static void MX_CAN2_Init(void)
{

  hcan2.Instance = CAN2;
  hcan2.Init.Prescaler = 5;
  hcan2.Init.Mode = CAN_MODE_NORMAL;
  hcan2.Init.SyncJumpWidth = CAN_SJW_1TQ;
  hcan2.Init.TimeSeg1 = CAN_BS1_15TQ;
  hcan2.Init.TimeSeg2 = CAN_BS2_2TQ;
  hcan2.Init.TimeTriggeredMode = DISABLE;
  hcan2.Init.AutoBusOff = DISABLE;
  hcan2.Init.AutoWakeUp = DISABLE;
  hcan2.Init.AutoRetransmission = DISABLE;
  hcan2.Init.ReceiveFifoLocked = DISABLE;
  hcan2.Init.TransmitFifoPriority = DISABLE;
  if (HAL_CAN_Init(&hcan2) != HAL_OK)
  {
    Error_Handler();
  }
  /* USER CODE BEGIN CAN2_Init 2 */

  COMM_setupCANFilter();

  /* USER CODE END CAN2_Init 2 */

}

static void MX_CRC_Init(void)
{

  hcrc.Instance = CRC;
  if (HAL_CRC_Init(&hcrc) != HAL_OK)
  {
    Error_Handler();
  }

}

static void MX_DMA2D_Init(void)
{

  hdma2d.Instance = DMA2D;
  hdma2d.Init.Mode = DMA2D_M2M;
  hdma2d.Init.ColorMode = DMA2D_OUTPUT_ARGB8888;
  hdma2d.Init.OutputOffset = 0;
  hdma2d.LayerCfg[1].InputOffset = 0;
  hdma2d.LayerCfg[1].InputColorMode = DMA2D_INPUT_ARGB8888;
  hdma2d.LayerCfg[1].AlphaMode = DMA2D_NO_MODIF_ALPHA;
  hdma2d.LayerCfg[1].InputAlpha = 0;
  if (HAL_DMA2D_Init(&hdma2d) != HAL_OK)
  {
    Error_Handler();
  }
  if (HAL_DMA2D_ConfigLayer(&hdma2d, 1) != HAL_OK)
  {
    Error_Handler();
  }

}

static void MX_I2C3_Init(void)
{

  hi2c3.Instance = I2C3;
  hi2c3.Init.ClockSpeed = 100000;
  hi2c3.Init.DutyCycle = I2C_DUTYCYCLE_2;
  hi2c3.Init.OwnAddress1 = 0;
  hi2c3.Init.AddressingMode = I2C_ADDRESSINGMODE_7BIT;
  hi2c3.Init.DualAddressMode = I2C_DUALADDRESS_DISABLE;
  hi2c3.Init.OwnAddress2 = 0;
  hi2c3.Init.GeneralCallMode = I2C_GENERALCALL_DISABLE;
  hi2c3.Init.NoStretchMode = I2C_NOSTRETCH_DISABLE;
  if (HAL_I2C_Init(&hi2c3) != HAL_OK)
  {
    Error_Handler();
  }

  /** Configure Analogue filter
  */
  if (HAL_I2CEx_ConfigAnalogFilter(&hi2c3, I2C_ANALOGFILTER_ENABLE) != HAL_OK)
  {
    Error_Handler();
  }

  /** Configure Digital filter
  */
  if (HAL_I2CEx_ConfigDigitalFilter(&hi2c3, 0) != HAL_OK)
  {
    Error_Handler();
  }

}

static void MX_LTDC_Init(void)
{

  LTDC_LayerCfgTypeDef pLayerCfg = {0};

  hltdc.Instance = LTDC;
  hltdc.Init.HSPolarity = LTDC_HSPOLARITY_AL;
  hltdc.Init.VSPolarity = LTDC_VSPOLARITY_AL;
  hltdc.Init.DEPolarity = LTDC_DEPOLARITY_AL;
  hltdc.Init.PCPolarity = LTDC_PCPOLARITY_IPC;
  hltdc.Init.HorizontalSync = 30;
  hltdc.Init.VerticalSync = 2;
  hltdc.Init.AccumulatedHBP = 89;
  hltdc.Init.AccumulatedVBP = 17;
  hltdc.Init.AccumulatedActiveW = 409;
  hltdc.Init.AccumulatedActiveH = 257;
  hltdc.Init.TotalWidth = 425;
  hltdc.Init.TotalHeigh = 261;
  hltdc.Init.Backcolor.Blue = 0;
  hltdc.Init.Backcolor.Green = 0;
  hltdc.Init.Backcolor.Red = 0;
  if (HAL_LTDC_Init(&hltdc) != HAL_OK)
  {
    Error_Handler();
  }
  pLayerCfg.WindowX0 = 0;
  pLayerCfg.WindowX1 = 320;
  pLayerCfg.WindowY0 = 0;
  pLayerCfg.WindowY1 = 234;
  pLayerCfg.PixelFormat = LTDC_PIXEL_FORMAT_RGB565;
  pLayerCfg.Alpha = 255;
  pLayerCfg.Alpha0 = 0;
  pLayerCfg.BlendingFactor1 = LTDC_BLENDING_FACTOR1_CA;
  pLayerCfg.BlendingFactor2 = LTDC_BLENDING_FACTOR2_CA;
  pLayerCfg.FBStartAdress = 0xD0000000;
  pLayerCfg.ImageWidth = 320;
  pLayerCfg.ImageHeight = 234;
  pLayerCfg.Backcolor.Blue = 0;
  pLayerCfg.Backcolor.Green = 0;
  pLayerCfg.Backcolor.Red = 0;
  if (HAL_LTDC_ConfigLayer(&hltdc, &pLayerCfg, 0) != HAL_OK)
  {
    Error_Handler();
  }

}

static void MX_RNG_Init(void)
{

  hrng.Instance = RNG;
  if (HAL_RNG_Init(&hrng) != HAL_OK)
  {
    Error_Handler();
  }

}

static void MX_SPI5_Init(void)
{

  /* SPI5 parameter configuration*/
  hspi5.Instance = SPI5;
  hspi5.Init.Mode = SPI_MODE_MASTER;
  hspi5.Init.Direction = SPI_DIRECTION_2LINES;
  hspi5.Init.DataSize = SPI_DATASIZE_8BIT;
  hspi5.Init.CLKPolarity = SPI_POLARITY_LOW;
  hspi5.Init.CLKPhase = SPI_PHASE_1EDGE;
  hspi5.Init.NSS = SPI_NSS_SOFT;
  hspi5.Init.BaudRatePrescaler = SPI_BAUDRATEPRESCALER_16;
  hspi5.Init.FirstBit = SPI_FIRSTBIT_MSB;
  hspi5.Init.TIMode = SPI_TIMODE_DISABLE;
  hspi5.Init.CRCCalculation = SPI_CRCCALCULATION_DISABLE;
  hspi5.Init.CRCPolynomial = 10;
  if (HAL_SPI_Init(&hspi5) != HAL_OK)
  {
    Error_Handler();
  }

}

static void MX_TIM1_Init(void)
{

  TIM_ClockConfigTypeDef sClockSourceConfig = {0};
  TIM_MasterConfigTypeDef sMasterConfig = {0};

  htim1.Instance = TIM1;
  htim1.Init.Prescaler = 0;
  htim1.Init.CounterMode = TIM_COUNTERMODE_UP;
  htim1.Init.Period = 65535;
  htim1.Init.ClockDivision = TIM_CLOCKDIVISION_DIV1;
  htim1.Init.RepetitionCounter = 0;
  htim1.Init.AutoReloadPreload = TIM_AUTORELOAD_PRELOAD_DISABLE;
  if (HAL_TIM_Base_Init(&htim1) != HAL_OK)
  {
    Error_Handler();
  }
  sClockSourceConfig.ClockSource = TIM_CLOCKSOURCE_INTERNAL;
  if (HAL_TIM_ConfigClockSource(&htim1, &sClockSourceConfig) != HAL_OK)
  {
    Error_Handler();
  }
  sMasterConfig.MasterOutputTrigger = TIM_TRGO_RESET;
  sMasterConfig.MasterSlaveMode = TIM_MASTERSLAVEMODE_DISABLE;
  if (HAL_TIMEx_MasterConfigSynchronization(&htim1, &sMasterConfig) != HAL_OK)
  {
    Error_Handler();
  }

}

/* FMC initialization function */
static void MX_FMC_Init(void)
{

  FMC_SDRAM_TimingTypeDef SdramTiming = {0};

  /** Perform the SDRAM1 memory initialization sequence
  */
  hsdram1.Instance = FMC_SDRAM_DEVICE;
  /* hsdram1.Init */
  hsdram1.Init.SDBank = FMC_SDRAM_BANK2;
  hsdram1.Init.ColumnBitsNumber = FMC_SDRAM_COLUMN_BITS_NUM_8;
  hsdram1.Init.RowBitsNumber = FMC_SDRAM_ROW_BITS_NUM_12;
  hsdram1.Init.MemoryDataWidth = FMC_SDRAM_MEM_BUS_WIDTH_16;
  hsdram1.Init.InternalBankNumber = FMC_SDRAM_INTERN_BANKS_NUM_4;
  hsdram1.Init.CASLatency = FMC_SDRAM_CAS_LATENCY_3;
  hsdram1.Init.WriteProtection = FMC_SDRAM_WRITE_PROTECTION_DISABLE;
  hsdram1.Init.SDClockPeriod = FMC_SDRAM_CLOCK_PERIOD_2;
  hsdram1.Init.ReadBurst = FMC_SDRAM_RBURST_DISABLE;
  hsdram1.Init.ReadPipeDelay = FMC_SDRAM_RPIPE_DELAY_1;
  /* SdramTiming */
  SdramTiming.LoadToActiveDelay = 2;
  SdramTiming.ExitSelfRefreshDelay = 7;
  SdramTiming.SelfRefreshTime = 4;
  SdramTiming.RowCycleDelay = 7;
  SdramTiming.WriteRecoveryTime = 3;
  SdramTiming.RPDelay = 2;
  SdramTiming.RCDDelay = 2;

  if (HAL_SDRAM_Init(&hsdram1, &SdramTiming) != HAL_OK)
  {
    Error_Handler( );
  }

  /* USER CODE BEGIN FMC_Init 2 */
  FMC_SDRAM_CommandTypeDef command;
  /* Program the SDRAM external device */
  BSP_SDRAM_Initialization_Sequence(&hsdram1, &command);
  /* USER CODE END FMC_Init 2 */
}

static void MX_GPIO_Init(void)
{
  GPIO_InitTypeDef GPIO_InitStruct = {0};

  /* GPIO Ports Clock Enable */
  __HAL_RCC_GPIOF_CLK_ENABLE();
  __HAL_RCC_GPIOH_CLK_ENABLE();
  __HAL_RCC_GPIOC_CLK_ENABLE();
  __HAL_RCC_GPIOA_CLK_ENABLE();
  __HAL_RCC_GPIOB_CLK_ENABLE();
  __HAL_RCC_GPIOG_CLK_ENABLE();
  __HAL_RCC_GPIOE_CLK_ENABLE();
  __HAL_RCC_GPIOD_CLK_ENABLE();

  /*Configure GPIO pin Output Level */
  HAL_GPIO_WritePin(GPIOC, NCS_MEMS_SPI_Pin|CSX_Pin, GPIO_PIN_RESET);

  /*Configure GPIO pin Output Level */
  HAL_GPIO_WritePin(ACP_RST_GPIO_Port, ACP_RST_Pin, GPIO_PIN_RESET);

  /*Configure GPIO pin Output Level */
  HAL_GPIO_WritePin(GPIOD, RDX_Pin|WRX_DCX_Pin, GPIO_PIN_RESET);

  /*Configure GPIO pin Output Level */
  HAL_GPIO_WritePin(GPIOG, LD3_Pin|LD4_Pin, GPIO_PIN_RESET);

  /*Configure GPIO pins : NCS_MEMS_SPI_Pin CSX_Pin */
  GPIO_InitStruct.Pin = NCS_MEMS_SPI_Pin|CSX_Pin;
  GPIO_InitStruct.Mode = GPIO_MODE_OUTPUT_PP;
  GPIO_InitStruct.Pull = GPIO_NOPULL;
  GPIO_InitStruct.Speed = GPIO_SPEED_FREQ_LOW;
  HAL_GPIO_Init(GPIOC, &GPIO_InitStruct);

  /*Configure GPIO pin : BLUE_BTN_Pin */
  GPIO_InitStruct.Pin = BLUE_BTN_Pin;
  GPIO_InitStruct.Mode = GPIO_MODE_IT_FALLING;
  GPIO_InitStruct.Pull = GPIO_NOPULL;
  HAL_GPIO_Init(BLUE_BTN_GPIO_Port, &GPIO_InitStruct);

  /*Configure GPIO pins : MEMS_INT1_Pin MEMS_INT2_Pin TP_INT1_Pin */
  GPIO_InitStruct.Pin = MEMS_INT1_Pin|MEMS_INT2_Pin|TP_INT1_Pin;
  GPIO_InitStruct.Mode = GPIO_MODE_EVT_RISING;
  GPIO_InitStruct.Pull = GPIO_NOPULL;
  HAL_GPIO_Init(GPIOA, &GPIO_InitStruct);

  /*Configure GPIO pin : ACP_RST_Pin */
  GPIO_InitStruct.Pin = ACP_RST_Pin;
  GPIO_InitStruct.Mode = GPIO_MODE_OUTPUT_PP;
  GPIO_InitStruct.Pull = GPIO_NOPULL;
  GPIO_InitStruct.Speed = GPIO_SPEED_FREQ_LOW;
  HAL_GPIO_Init(ACP_RST_GPIO_Port, &GPIO_InitStruct);

  /*Configure GPIO pin : BOOT1_Pin */
  GPIO_InitStruct.Pin = BOOT1_Pin;
  GPIO_InitStruct.Mode = GPIO_MODE_INPUT;
  GPIO_InitStruct.Pull = GPIO_NOPULL;
  HAL_GPIO_Init(BOOT1_GPIO_Port, &GPIO_InitStruct);

  /*Configure GPIO pin : TE_Pin */
  GPIO_InitStruct.Pin = TE_Pin;
  GPIO_InitStruct.Mode = GPIO_MODE_INPUT;
  GPIO_InitStruct.Pull = GPIO_NOPULL;
  HAL_GPIO_Init(TE_GPIO_Port, &GPIO_InitStruct);

  /*Configure GPIO pins : RDX_Pin WRX_DCX_Pin */
  GPIO_InitStruct.Pin = RDX_Pin|WRX_DCX_Pin;
  GPIO_InitStruct.Mode = GPIO_MODE_OUTPUT_PP;
  GPIO_InitStruct.Pull = GPIO_NOPULL;
  GPIO_InitStruct.Speed = GPIO_SPEED_FREQ_LOW;
  HAL_GPIO_Init(GPIOD, &GPIO_InitStruct);

  /*Configure GPIO pins : LD3_Pin LD4_Pin */
  GPIO_InitStruct.Pin = LD3_Pin|LD4_Pin;
  GPIO_InitStruct.Mode = GPIO_MODE_OUTPUT_PP;
  GPIO_InitStruct.Pull = GPIO_NOPULL;
  GPIO_InitStruct.Speed = GPIO_SPEED_FREQ_LOW;
  HAL_GPIO_Init(GPIOG, &GPIO_InitStruct);

  /* EXTI interrupt init*/
  HAL_NVIC_SetPriority(EXTI0_IRQn, 5, 0);
  HAL_NVIC_EnableIRQ(EXTI0_IRQn);

}

/* USER CODE BEGIN 4 */

/**
  * @brief  Perform the SDRAM external memory initialization sequence
  * @param  hsdram: SDRAM handle
  * @param  Command: Pointer to SDRAM command structure
  * @retval None
  */
static void BSP_SDRAM_Initialization_Sequence(SDRAM_HandleTypeDef *hsdram, FMC_SDRAM_CommandTypeDef *Command)
{
  __IO uint32_t tmpmrd =0;

  /* Step 1:  Configure a clock configuration enable command */
  Command->CommandMode             = FMC_SDRAM_CMD_CLK_ENABLE;
  Command->CommandTarget           = FMC_SDRAM_CMD_TARGET_BANK2;
  Command->AutoRefreshNumber       = 1;
  Command->ModeRegisterDefinition  = 0;

  /* Send the command */
  HAL_SDRAM_SendCommand(hsdram, Command, SDRAM_TIMEOUT);

  /* Step 2: Insert 100 us minimum delay */
  /* Inserted delay is equal to 1 ms due to systick time base unit (ms) */
  HAL_Delay(1);

  /* Step 3: Configure a PALL (precharge all) command */
  Command->CommandMode             = FMC_SDRAM_CMD_PALL;
  Command->CommandTarget           = FMC_SDRAM_CMD_TARGET_BANK2;
  Command->AutoRefreshNumber       = 1;
  Command->ModeRegisterDefinition  = 0;

  /* Send the command */
  HAL_SDRAM_SendCommand(hsdram, Command, SDRAM_TIMEOUT);

  /* Step 4: Configure an Auto Refresh command */
  Command->CommandMode             = FMC_SDRAM_CMD_AUTOREFRESH_MODE;
  Command->CommandTarget           = FMC_SDRAM_CMD_TARGET_BANK2;
  Command->AutoRefreshNumber       = 4;
  Command->ModeRegisterDefinition  = 0;

  /* Send the command */
  HAL_SDRAM_SendCommand(hsdram, Command, SDRAM_TIMEOUT);

  /* Step 5: Program the external memory mode register */
  tmpmrd = (uint32_t)SDRAM_MODEREG_BURST_LENGTH_1          |
           SDRAM_MODEREG_BURST_TYPE_SEQUENTIAL   |
           SDRAM_MODEREG_CAS_LATENCY_3           |
           SDRAM_MODEREG_OPERATING_MODE_STANDARD |
           SDRAM_MODEREG_WRITEBURST_MODE_SINGLE;

  Command->CommandMode             = FMC_SDRAM_CMD_LOAD_MODE;
  Command->CommandTarget           = FMC_SDRAM_CMD_TARGET_BANK2;
  Command->AutoRefreshNumber       = 1;
  Command->ModeRegisterDefinition  = tmpmrd;

  /* Send the command */
  HAL_SDRAM_SendCommand(hsdram, Command, SDRAM_TIMEOUT);

  /* Step 6: Set the refresh rate counter */
  /* Set the device refresh rate */
  HAL_SDRAM_ProgramRefreshRate(hsdram, REFRESH_COUNT);
}

/**
  * @brief  IOE Low Level Initialization.
  */
void IOE_Init(void)
{
  // Dummy function called when initializing to stmpe811 to setup the i2c.
  // This is done with cubemx and is therfore not done here.
}

/**
  * @brief  IOE Low Level Interrupt configuration.
  */
void IOE_ITConfig(void)
{
  // Dummy function called when initializing to stmpe811 to setup interupt for the i2c.
  // The interupt is not used in our case, therefore nothing is done here.
}

/**
  * @brief  IOE Writes single data operation.
  * @param  Addr: I2C Address
  * @param  Reg: Reg Address
  * @param  Value: Data to be written
  */
void IOE_Write(uint8_t Addr, uint8_t Reg, uint8_t Value)
{
  I2C3_WriteData(Addr, Reg, Value);
}

/**
  * @brief  IOE Reads single data.
  * @param  Addr: I2C Address
  * @param  Reg: Reg Address
  * @retval The read data
  */
uint8_t IOE_Read(uint8_t Addr, uint8_t Reg)
{
  return I2C3_ReadData(Addr, Reg);
}

/**
  * @brief  IOE Reads multiple data.
  * @param  Addr: I2C Address
  * @param  Reg: Reg Address
  * @param  pBuffer: pointer to data buffer
  * @param  Length: length of the data
  * @retval 0 if no problems to read multiple data
  */
uint16_t IOE_ReadMultiple(uint8_t Addr, uint8_t Reg, uint8_t *pBuffer, uint16_t Length)
{
  return I2C3_ReadBuffer(Addr, Reg, pBuffer, Length);
}

/**
  * @brief  IOE Delay.
  * @param  Delay in ms
  */
void IOE_Delay(uint32_t Delay)
{
  HAL_Delay(Delay);
}

/**
  * @brief  Writes a value in a register of the device through BUS.
  * @param  Addr: Device address on BUS Bus.
  * @param  Reg: The target register address to write
  * @param  Value: The target register value to be written
  */
static void I2C3_WriteData(uint8_t Addr, uint8_t Reg, uint8_t Value)
{
  HAL_StatusTypeDef status = HAL_OK;

  status = HAL_I2C_Mem_Write(&hi2c3, Addr, (uint16_t)Reg, I2C_MEMADD_SIZE_8BIT, &Value, 1, I2c3Timeout);

  /* Check the communication status */
  if(status != HAL_OK)
  {
    /* Re-Initialize the BUS */
    //I2Cx_Error();
  }
}

/**
  * @brief  Reads a register of the device through BUS.
  * @param  Addr: Device address on BUS Bus.
  * @param  Reg: The target register address to write
  * @retval Data read at register address
  */
static uint8_t I2C3_ReadData(uint8_t Addr, uint8_t Reg)
{
  HAL_StatusTypeDef status = HAL_OK;
  uint8_t value = 0;

  status = HAL_I2C_Mem_Read(&hi2c3, Addr, Reg, I2C_MEMADD_SIZE_8BIT, &value, 1, I2c3Timeout);

  /* Check the communication status */
  if(status != HAL_OK)
  {
    /* Re-Initialize the BUS */
    //I2Cx_Error();

  }
  return value;
}

/**
  * @brief  Reads multiple data on the BUS.
  * @param  Addr: I2C Address
  * @param  Reg: Reg Address
  * @param  pBuffer: pointer to read data buffer
  * @param  Length: length of the data
  * @retval 0 if no problems to read multiple data
  */
static uint8_t I2C3_ReadBuffer(uint8_t Addr, uint8_t Reg, uint8_t *pBuffer, uint16_t Length)
{
  HAL_StatusTypeDef status = HAL_OK;

  status = HAL_I2C_Mem_Read(&hi2c3, Addr, (uint16_t)Reg, I2C_MEMADD_SIZE_8BIT, pBuffer, Length, I2c3Timeout);

  /* Check the communication status */
  if(status == HAL_OK)
  {
    return 0;
  }
  else
  {
    /* Re-Initialize the BUS */
    //I2Cx_Error();

    return 1;
  }
}
/* USER CODE END 4 */

void StartHardwareTask(void *argument)
{
  /* USER CODE BEGIN 5 */
  /* Infinite loop */
  for(;;)
  {
    DBGD_tick();
  }
  /* USER CODE END 5 */
}

void StartTGFXTask(void *argument)
{
  /* USER CODE BEGIN StartTGFXTask */
  MX_TouchGFX_Process();
  /* Infinite loop */
  for(;;)
  {
    osDelay(1);
  }
  /* USER CODE END StartTGFXTask */
}

void StartLcdDebugTask(void *argument)
{
  /* USER CODE BEGIN StartLcdDebugTask */
  /* Infinite loop */
  for(;;)
  {
    DBGS_tick();
  }
  /* USER CODE END StartLcdDebugTask */
}

void HAL_TIM_PeriodElapsedCallback(TIM_HandleTypeDef *htim)
{
  if (htim->Instance == TIM6) {
    HAL_IncTick();
  }
}

void Error_Handler(void)
{
  __disable_irq();
  while (1)
  {
  }
}
